# soc-dvt-2753c12 register map
Vendor: litex
Registers are 32-bit, read-write, reset 0x0 unless marked. A register's access mark holds for its fields unless they carry their own. Offsets are from the block's base; [hi:lo] are bit positions.

## SRAM_EXT
Base 0xF000B000
0x00 CONFIG_STATUS
  [31:0] mode — The current configuration mode of the SRAM
0x04 READ_CONFIG
  [0] trigger — Writing to this bit triggers the SRAM mode status read update

## MEMLCD
Base 0xF000C000
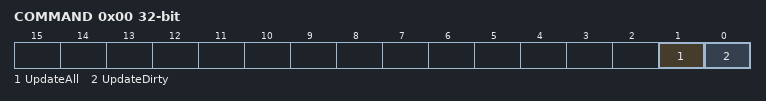
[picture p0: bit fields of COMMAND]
0x00 COMMAND
  [1] UpdateAll — Update full screen regardless of tag state
  [0] UpdateDirty — Write a ``1`` to flush dirty lines to the LCD
0x04 BUSY — A ``1`` indicates that the block is currently updating the LCD
  [0] busy
0x08 PRESCALER reset 0x63 — Prescaler value. LCD clock is module ``(clock / (prescaler+1))``. Reset value: ``99``, so for a default sysclk of 100MHz this yields an LCD ``SCLK`` of 1MHz
  [7:0] prescaler
0x0C EV_STATUS — This register contains the current raw level of the done event trigger. Writes to this register have no effect.
  [0] done — Level of the ``done`` event
0x10 EV_PENDING — When a done event occurs, the corresponding bit will be set in this register. To clear the Event, set the corresponding bit in this register.
  [0] done — `1` if a `done` event occurred. This Event is triggered on a **falling** edge.
0x14 EV_ENABLE — This register enables the corresponding done events. Write a ``0`` to this register to disable individual events.
  [0] done — Write a ``1`` to enable the ``done`` Event
0x18 DEVBOOT
  [0] devboot — When set to ``1``, permanently add a strike-through on the top of the screen. Cannot be cleared, except by a full reset. Do not rely on this register to determine if a devboot has happened; the *register* may be cleared, but the internal hardware bit cannot be.
0x1C DEVSTATUS — Reads back as ``1`` if a devboot was set anywhere along the boot chain. This is a read-only register and reflects ground truth.
  [0] devstatus

## COM
Base 0xF000D000
0x00 TX — Tx data, for COPI. Note: 32-bit CSRs are required for this block to work!
  [15:0] tx
0x04 RX — Rx data, from CIPO
  [15:0] rx
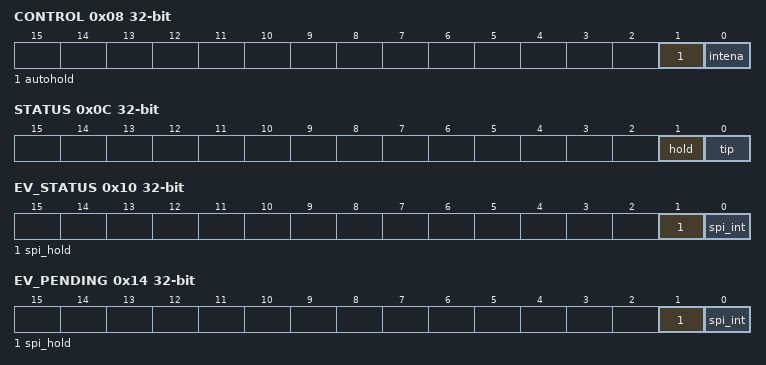
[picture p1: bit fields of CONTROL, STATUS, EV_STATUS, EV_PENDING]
0x08 CONTROL
  [1] autohold — Disallow transmission start if hold if asserted
  [0] intena — Enable interrupt on transaction finished
0x0C STATUS
  [1] hold — Set when peripheral asserts hold
  [0] tip — Set when transaction is in progress
0x10 EV_STATUS — This register contains the current raw level of the spi_hold event trigger. Writes to this register have no effect.
  [1] spi_hold — Level of the ``spi_hold`` event
  [0] spi_int — Level of the ``spi_int`` event
0x14 EV_PENDING — When a spi_hold event occurs, the corresponding bit will be set in this register. To clear the Event, set the corresponding bit in this register.
  [1] spi_hold — `1` if a `spi_hold` event occurred. This Event is triggered on a **falling** edge.
  [0] spi_int — `1` if a `spi_int` event occurred. This Event is triggered on a **falling** edge.
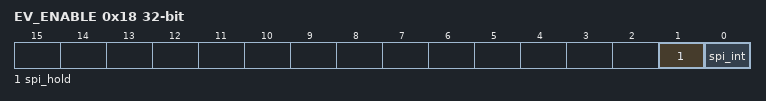
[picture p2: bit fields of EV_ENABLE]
0x18 EV_ENABLE — This register enables the corresponding spi_hold events. Write a ``0`` to this register to disable individual events.
  [1] spi_hold — Write a ``1`` to enable the ``spi_hold`` Event
  [0] spi_int — Write a ``1`` to enable the ``spi_int`` Event

## I2C
Base 0xF000E000
0x00 PRESCALE reset 0xFFFF — Prescaler value. Set to (module clock / (5 * I2C freq) - 1). Example: if module clock is equal to sysclk; syclk is 100MHz; and I2C freq is 100kHz, then prescaler is (100MHz / (5 * 100kHz) - 1) = 199. Reset value: 0xFFFF
  [15:0] prescale
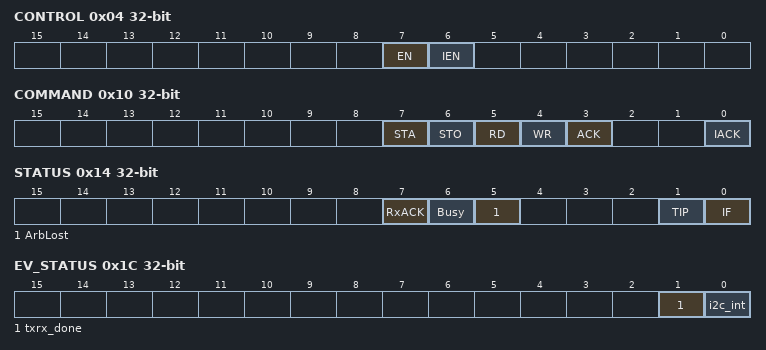
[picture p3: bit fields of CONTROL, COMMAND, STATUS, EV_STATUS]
0x04 CONTROL
  [7] EN — When set to `1`, the core is enabled.
  [6] IEN — When set to `1`, interrupts are enabled.
0x08 TXR — Next byte to transmit to slave devices. LSB indicates R/W during address phases, `1` for reading from slaves, `0` for writing to slaves
  [7:0] txr
0x0C RXR — Data being read from slaved devices
  [7:0] rxr
0x10 COMMAND
  [7] STA — generate (repeated) start condition
  [6] STO — generate stop condition
  [5] RD — read from slave
  [4] WR — write to slave
  [3] ACK — when a receiver, sent ack (`ACK=0`) or nack (`ACK=1`)
  [0] IACK — Interrupt acknowledge; when set, clears a pending interrupt
0x14 STATUS
  [7] RxACK — Received acknowledge from slave. 1 = no ack received, 0 = ack received
  [6] Busy — I2C block is busy processing the latest command
  [5] ArbLost — Set when arbitration for the bus is lost
  [1] TIP — transfer in progress
  [0] IF — Interrupt flag, This bit is set when an interrupt is pending, which will cause a processor interrupt request if the IEN bit is set. The Interrupt Flag is set upon the completion of one byte of data transfer.
0x18 CORE_RESET
  [0] reset — Write `1` for a synchronous reset of the I2C core. Does not reset the prescale value. This signal is outside of the OpenCores spec.
0x1C EV_STATUS — Triggered on the falling edge of TIP
  [1] txrx_done — Level of the ``txrx_done`` event
  [0] i2c_int — Level of the ``i2c_int`` event
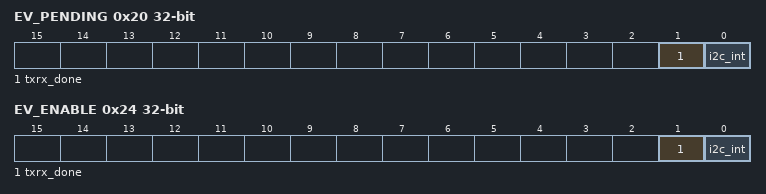
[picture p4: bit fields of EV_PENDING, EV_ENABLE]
0x20 EV_PENDING — Triggered on the falling edge of TIP
  [1] txrx_done — Triggered on the falling edge of TIP
  [0] i2c_int — Triggered when arbitration is lost or transaction done. Requires IACK write to clear or else it will re-trigger.
0x24 EV_ENABLE — Triggered on the falling edge of TIP
  [1] txrx_done — Write a ``1`` to enable the ``txrx_done`` Event
  [0] i2c_int — Write a ``1`` to enable the ``i2c_int`` Event
